# STM32H5E4 register map
File version: 1.0
CPU: CM33 r0p0, little endian, MPU, FPU, 4 interrupt priority bits
Registers are 32-bit, read-write, reset 0x0 unless marked. A register's access mark holds for its fields unless they carry their own. Offsets are from the block's base; [hi:lo] are bit positions; 'fields as' and 'values as' point back to an identical list.

## COMP — COMP register block
Base 0x40004000
Same registers: COMP_S 0x50004000
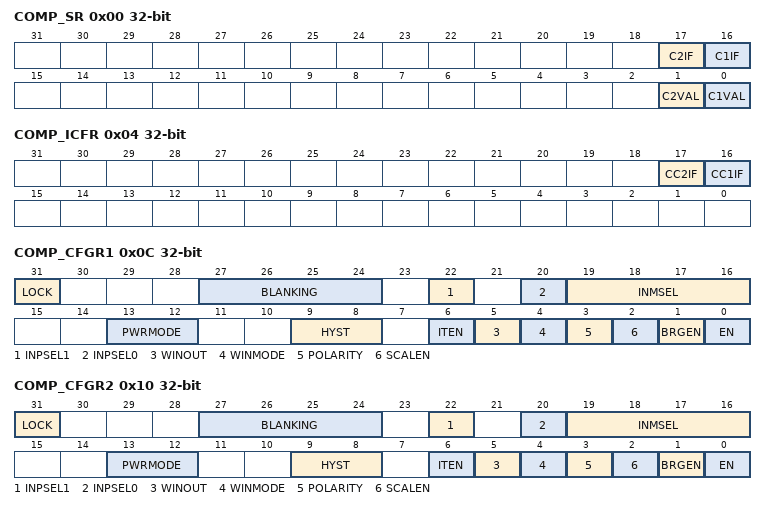
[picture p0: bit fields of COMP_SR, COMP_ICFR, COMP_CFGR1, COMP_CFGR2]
0x00 COMP_SR ro — Comparator status register
  [17] C2IF — COMP2 Channel interrupt flag
  [16] C1IF — COMP1 Channel interrupt flag
  [1] C2VAL — COMP2 Channel output status bit
  [0] C1VAL — COMP1 Channel output status bit
0x04 COMP_ICFR — Comparator interrupt clear flag register
  [17] CC2IF — Clear COMP2 Channel interrupt flag
  [16] CC1IF — Clear COMP1 Channel interrupt flag
0x0C COMP_CFGR1 — Comparator configuration register 1
  [31] LOCK
    0=COMP_CFGR1[31:0] register is read/write; 1=COMP_CFGR1[31:0] register is read-only
  [27:24] BLANKING — COMP1 Channel blanking source selection
  [22] INPSEL1 — COMP1 non-inverting input selection
  [20] INPSEL0 — COMP1 non-inverting input selection
  [19:16] INMSEL — COMP1 Channel inverting input selection
  [13:12] PWRMODE — Power mode of the COMP Channel
    0=High speed / full power; 1=Medium speed / medium power; 2=Medium speed / medium power; 3=Ultra low power / ultra-low-power
  [9:8] HYST — COMP Channel hysteresis selection
    0=No hysteresis; 1=Low hysteresis; 2=Medium hysteresis; 3=High hysteresis
  [6] ITEN — COMP Channel interrupt enable
    0=Interrupt generation disabled for COMP Channel; 1=Interrupt generation enabled for COMP Channel
  [5] WINOUT — COMP1 output selector
    0=COMP1_VALUE; 1=COMP1_VALUE XOR COMP2_VALUE (required for window mode, see Figure331: Window comparators functional block diagram)
  [4] WINMODE — COMP1 non-inverting input selector for window mode
    0=Signal selected with INPSEL[1:0]; 1=COMP2_INP signal of COMP2 (required for window mode, see Figure331: Window comparators functional block diagram)
  [3] POLARITY — COMP Channel polarity selection
    0=COMP Channel output is not inverted; 1=COMP Channel output is inverted
  [2] SCALEN — Voltage scaler enable
    0=Vless thansub>REFINTless than/sub> scaler disabled; 1=Vless thansub>REFINTless than/sub> scaler enabled
  [1] BRGEN — Scaler bridge enable
    0=Scaler resistor bridge disabled; 1=Scaler resistor bridge enabled
  [0] EN — COMP Channel enable
    0=Disable; 1=Enable
0x10 COMP_CFGR2 — Comparator configuration register 2
  [31] LOCK
    0=COMP_CFGR2[31:0] register is read/write; 1=COMP_CFGR2[31:0] register is read-only
  [27:24] BLANKING — COMP2 Channel blanking source selection
  [22] INPSEL1 — COMP2 non-inverting input selection
  [20] INPSEL0 — COMP2 non-inverting input selection
  [19:16] INMSEL — COMP2 Channel inverting input selection
  [13:12] PWRMODE — Power mode of the COMP Channel
    values as COMP_CFGR1.PWRMODE
  [9:8] HYST — COMP Channel hysteresis selection
    values as COMP_CFGR1.HYST
  [6] ITEN — COMP Channel interrupt enable
    values as COMP_CFGR1.ITEN
  [5] WINOUT — COMP2 output selector
    0=COMP2_VALUE; 1=COMP1_VALUE XOR COMP2_VALUE (required for window mode, see Figure331: Window comparators functional block diagram)
  [4] WINMODE — COMP2 non-inverting input selector for window mode
    0=Signal selected with INPSEL[1:0]; 1=COMP1_INP signal of COMP1 (required for window mode, see Figure331: Window comparators functional block diagram)
  [3] POLARITY — COMP Channel polarity selection
    values as COMP_CFGR1.POLARITY
  [2] SCALEN — Voltage scaler enable
    values as COMP_CFGR1.SCALEN
  [1] BRGEN — Scaler bridge enable
    values as COMP_CFGR1.BRGEN
  [0] EN — COMP Channel enable
    0=Disable; 1=Enable

## CORDIC — CORDIC register block
Base 0x40023800
Same registers: CORDIC_S 0x50023800
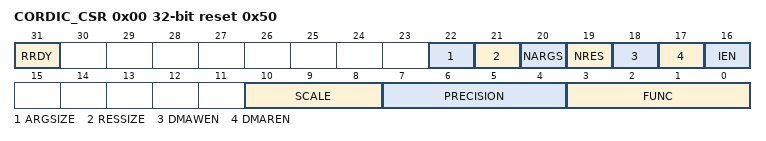
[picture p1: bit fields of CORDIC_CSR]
0x00 CORDIC_CSR reset 0x50 — CORDIC control/status register
  [31] RRDY ro — Result ready flag
    0=No new data in output register; 1=CORDIC_RDATA register contains new data
  [22] ARGSIZE — Width of input data
    0=32-bit; 1=16-bit
  [21] RESSIZE — Width of output data
    0=32-bit; 1=16-bit
  [20] NARGS — Number of arguments expected by the CORDIC_WDATA register
    0=Only one 32-bit write (or two 16-bit values if ARGSIZE = 1) is needed for the next calculation; 1=Two 32-bit values must be written to the CORDIC_WDATA register to trigger the next calculation
  [19] NRES — Number of results in the CORDIC_RDATA register
    0=Only one 32-bit value (or two 16-bit values if RESSIZE = 1) is transferred to the CORDIC_RDATA register on completion of the next calculation; 1=Two 32-bit values are transferred to the CORDIC_RDATA register on completion of the next calculation
  [18] DMAWEN — Enable DMA write channel
    0=Disabled; 1=Enabled
  [17] DMAREN — Enable DMA read channel
    0=Disabled; 1=Enabled
  [16] IEN — Enable interrupt.
    0=Disabled; 1=Enabled
  [10:8] SCALE — Scaling factor
  [7:4] PRECISION — Precision required (number of iterations)
  [3:0] FUNC — Function
    0=Cosine; 1=Sine
0x04 CORDIC_WDATA wo reset not defined — CORDIC argument register
  [31:0] ARG — Function input arguments
0x08 CORDIC_RDATA ro — CORDIC result register
  [31:0] RES — Function result

## Notices in the file
Copyright (c) 2025 STMicroelectronics.
SPDX-License-Identifier: Apache-2.0
Licensed under the Apache License, Version 2.0 (the "License");
you may not use this file except in compliance with the License.
You may obtain a copy of the License at
http://www.apache.org/licenses/LICENSE-2.0
Unless required by applicable law or agreed to in writing, software
distributed under the License is distributed on an "AS IS" BASIS,
WITHOUT WARRANTIES OR CONDITIONS OF ANY KIND, either express or implied.
See the License for the specific language governing permissions and
limitations under the License.
